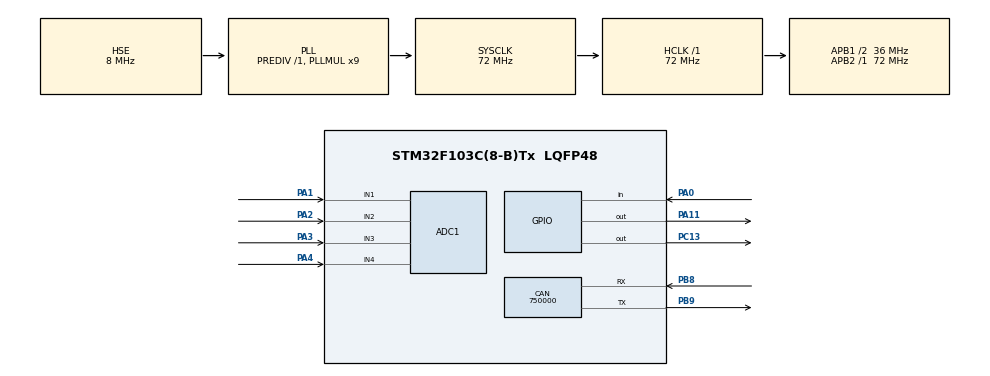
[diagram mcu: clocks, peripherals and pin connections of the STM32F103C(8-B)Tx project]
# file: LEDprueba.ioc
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Mcu.Family=STM32F1
RCC.PLLSourceVirtual=RCC_PLLSOURCE_HSE
FREERTOS.Tasks01=defaultTask,24,128,StartDefaultTask,Default,NULL,Dynamic,NULL,NULL;myTask02,24,128,StartTask02,Default,NULL,Dynamic,NULL,NULL;myTask03,16,128,StartTask03,Default,NULL,Dynamic,NULL,NULL
ADC1.Rank-0\#ChannelRegularConversion=1
PD1-OSC_OUT.Mode=HSE-External-Oscillator
SH.ADCx_IN2.0=ADC1_IN2,IN2
CAN.CalculateBaudRate=750000
PC13-TAMPER-RTC.Signal=GPIO_Output
PD0-OSC_IN.Signal=RCC_OSC_IN
RCC.APB1CLKDivider=RCC_HCLK_DIV2
CAN.CalculateTimeBit=1333.33
RCC.SYSCLKSource=RCC_SYSCLKSOURCE_PLLCLK
ProjectManager.StackSize=0x400
PA0-WKUP.Signal=GPIO_Input
VP_FREERTOS_VS_CMSIS_V2.Mode=CMSIS_V2
PD1-OSC_OUT.Signal=RCC_OSC_OUT
PA13.Signal=SYS_JTMS-SWDIO
ProjectManager.TargetToolchain=STM32CubeIDE
RCC.HCLKFreq_Value=72000000
SH.ADCx_IN3.0=ADC1_IN3,IN3
PB9.Mode=CAN_Activate
RCC.APB2TimFreq_Value=72000000
RCC.USBFreq_Value=72000000
PA1.Signal=ADCx_IN1
RCC.AHBFreq_Value=72000000
PD0-OSC_IN.Mode=HSE-External-Oscillator
ADC1.Channel-0\#ChannelRegularConversion=ADC_CHANNEL_1
board=custom
RCC.PLLMUL=RCC_PLL_MUL9
RCC.APB2Freq_Value=72000000
PA14.Mode=Serial_Wire
SH.ADCx_IN4.0=ADC1_IN4,IN4
PA13.Mode=Serial_Wire
Mcu.Name=STM32F103C(8-B)Tx
CAN.CalculateTimeQuantum=444.44444444444446
ADC1.SamplingTime-0\#ChannelRegularConversion=ADC_SAMPLETIME_1CYCLE_5
PA2.Signal=ADCx_IN2
PA4.Signal=ADCx_IN4
RCC.SYSCLKFreq_VALUE=72000000
Mcu.Package=LQFP48
PB9.Signal=CAN_TX
ADC1.master=1
PA11.Signal=GPIO_Output
PA14.Signal=SYS_JTCK-SWCLK
ProjectManager.HeapSize=0x200
NVIC.PriorityGroup=NVIC_PRIORITYGROUP_4
ADC1.NbrOfConversionFlag=1
SH.ADCx_IN1.0=ADC1_IN1,IN1
PB8.Mode=CAN_Activate
RCC.APB1TimFreq_Value=72000000
PB8.Signal=CAN_RX
RCC.APB1Freq_Value=36000000
PA3.Signal=ADCx_IN3

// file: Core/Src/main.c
/* USER CODE BEGIN Header */
/**
  ******************************************************************************
  * @file           : main.c
  * @brief          : Main program body
  ******************************************************************************
  * @attention
  *
  * <h2><center>&copy; Copyright (c) 2021 STMicroelectronics.
  * All rights reserved.</center></h2>
  *
  * This software component is licensed by ST under BSD 3-Clause license,
  * the "License"; You may not use this file except in compliance with the
  * License. You may obtain a copy of the License at:
  *                        opensource.org/licenses/BSD-3-Clause
  *
  ******************************************************************************
  */
/* USER CODE END Header */
#include "main.h"
#include "cmsis_os.h"

ADC_HandleTypeDef hadc1;

CAN_HandleTypeDef hcan;

/* Definitions for defaultTask */
osThreadId_t defaultTaskHandle;
const osThreadAttr_t defaultTask_attributes = {
  .name = "defaultTask",
  .stack_size = 128 * 4,
  .priority = (osPriority_t) osPriorityNormal,
};
/* Definitions for myTask02 */
osThreadId_t myTask02Handle;
const osThreadAttr_t myTask02_attributes = {
  .name = "myTask02",
  .stack_size = 128 * 4,
  .priority = (osPriority_t) osPriorityNormal,
};
/* Definitions for myTask03 */
osThreadId_t myTask03Handle;
const osThreadAttr_t myTask03_attributes = {
  .name = "myTask03",
  .stack_size = 128 * 4,
  .priority = (osPriority_t) osPriorityBelowNormal,
};

void SystemClock_Config(void);
static void MX_GPIO_Init(void);
static void MX_ADC1_Init(void);
static void MX_CAN_Init(void);
void StartDefaultTask(void *argument);
void StartTask02(void *argument);
void StartTask03(void *argument);

int main(void)
{

  /* MCU Configuration--------------------------------------------------------*/

  /* Reset of all peripherals, Initializes the Flash interface and the Systick. */
  HAL_Init();

  /* Configure the system clock */
  SystemClock_Config();

  /* Initialize all configured peripherals */
  MX_GPIO_Init();
  MX_ADC1_Init();
  MX_CAN_Init();
  /* USER CODE BEGIN 2 */
  //filter config
  //CAN_FilterConfig();
  //Start listening for CAN traffic with IT
 // HAL_CAN_Receive_IT(&hcan1, CAN_FIFO0);

  /* USER CODE END 2 */

  /* Init scheduler */
  osKernelInitialize();

  /* Create the thread(s) */
  /* creation of defaultTask */
  defaultTaskHandle = osThreadNew(StartDefaultTask, NULL, &defaultTask_attributes);

  /* creation of myTask02 */
  myTask02Handle = osThreadNew(StartTask02, NULL, &myTask02_attributes);

  /* creation of myTask03 */
  myTask03Handle = osThreadNew(StartTask03, NULL, &myTask03_attributes);

  /* Start scheduler */
  osKernelStart();

  /* We should never get here as control is now taken by the scheduler */
  /* Infinite loop */
  while (1)
  {

  }
}

void SystemClock_Config(void)
{
  RCC_OscInitTypeDef RCC_OscInitStruct = {0};
  RCC_ClkInitTypeDef RCC_ClkInitStruct = {0};
  RCC_PeriphCLKInitTypeDef PeriphClkInit = {0};

  /** Initializes the RCC Oscillators according to the specified parameters
  * in the RCC_OscInitTypeDef structure.
  */
  RCC_OscInitStruct.OscillatorType = RCC_OSCILLATORTYPE_HSE;
  RCC_OscInitStruct.HSEState = RCC_HSE_ON;
  RCC_OscInitStruct.HSEPredivValue = RCC_HSE_PREDIV_DIV1;
  RCC_OscInitStruct.HSIState = RCC_HSI_ON;
  RCC_OscInitStruct.PLL.PLLState = RCC_PLL_ON;
  RCC_OscInitStruct.PLL.PLLSource = RCC_PLLSOURCE_HSE;
  RCC_OscInitStruct.PLL.PLLMUL = RCC_PLL_MUL9;
  if (HAL_RCC_OscConfig(&RCC_OscInitStruct) != HAL_OK)
  {
    Error_Handler();
  }
  /** Initializes the CPU, AHB and APB buses clocks
  */
  RCC_ClkInitStruct.ClockType = RCC_CLOCKTYPE_HCLK|RCC_CLOCKTYPE_SYSCLK
                              |RCC_CLOCKTYPE_PCLK1|RCC_CLOCKTYPE_PCLK2;
  RCC_ClkInitStruct.SYSCLKSource = RCC_SYSCLKSOURCE_PLLCLK;
  RCC_ClkInitStruct.AHBCLKDivider = RCC_SYSCLK_DIV1;
  RCC_ClkInitStruct.APB1CLKDivider = RCC_HCLK_DIV2;
  RCC_ClkInitStruct.APB2CLKDivider = RCC_HCLK_DIV1;

  if (HAL_RCC_ClockConfig(&RCC_ClkInitStruct, FLASH_LATENCY_2) != HAL_OK)
  {
    Error_Handler();
  }
  PeriphClkInit.PeriphClockSelection = RCC_PERIPHCLK_ADC;
  PeriphClkInit.AdcClockSelection = RCC_ADCPCLK2_DIV2;
  if (HAL_RCCEx_PeriphCLKConfig(&PeriphClkInit) != HAL_OK)
  {
    Error_Handler();
  }
}

static void MX_ADC1_Init(void)
{

  ADC_ChannelConfTypeDef sConfig = {0};

  /** Common config
  */
  hadc1.Instance = ADC1;
  hadc1.Init.ScanConvMode = ADC_SCAN_DISABLE;
  hadc1.Init.ContinuousConvMode = DISABLE;
  hadc1.Init.DiscontinuousConvMode = DISABLE;
  hadc1.Init.ExternalTrigConv = ADC_SOFTWARE_START;
  hadc1.Init.DataAlign = ADC_DATAALIGN_RIGHT;
  hadc1.Init.NbrOfConversion = 1;
  if (HAL_ADC_Init(&hadc1) != HAL_OK)
  {
    Error_Handler();
  }
  /** Configure Regular Channel
  */
  sConfig.Channel = ADC_CHANNEL_1;
  sConfig.Rank = ADC_REGULAR_RANK_1;
  sConfig.SamplingTime = ADC_SAMPLETIME_1CYCLE_5;
  if (HAL_ADC_ConfigChannel(&hadc1, &sConfig) != HAL_OK)
  {
    Error_Handler();
  }

}

static void MX_CAN_Init(void)
{

  hcan.Instance = CAN1;
  hcan.Init.Prescaler = 16;
  hcan.Init.Mode = CAN_MODE_NORMAL;
  hcan.Init.SyncJumpWidth = CAN_SJW_1TQ;
  hcan.Init.TimeSeg1 = CAN_BS1_1TQ;
  hcan.Init.TimeSeg2 = CAN_BS2_1TQ;
  hcan.Init.TimeTriggeredMode = DISABLE;
  hcan.Init.AutoBusOff = DISABLE;
  hcan.Init.AutoWakeUp = DISABLE;
  hcan.Init.AutoRetransmission = DISABLE;
  hcan.Init.ReceiveFifoLocked = DISABLE;
  hcan.Init.TransmitFifoPriority = DISABLE;
  if (HAL_CAN_Init(&hcan) != HAL_OK)
  {
    Error_Handler();
  }

}

static void MX_GPIO_Init(void)
{
  GPIO_InitTypeDef GPIO_InitStruct = {0};

  /* GPIO Ports Clock Enable */
  __HAL_RCC_GPIOC_CLK_ENABLE();
  __HAL_RCC_GPIOD_CLK_ENABLE();
  __HAL_RCC_GPIOA_CLK_ENABLE();
  __HAL_RCC_GPIOB_CLK_ENABLE();

  /*Configure GPIO pin Output Level */
  HAL_GPIO_WritePin(GPIOC, GPIO_PIN_13, GPIO_PIN_RESET);

  /*Configure GPIO pin Output Level */
  HAL_GPIO_WritePin(GPIOA, GPIO_PIN_11, GPIO_PIN_RESET);

  /*Configure GPIO pin : PC13 */
  GPIO_InitStruct.Pin = GPIO_PIN_13;
  GPIO_InitStruct.Mode = GPIO_MODE_OUTPUT_PP;
  GPIO_InitStruct.Pull = GPIO_NOPULL;
  GPIO_InitStruct.Speed = GPIO_SPEED_FREQ_LOW;
  HAL_GPIO_Init(GPIOC, &GPIO_InitStruct);

  /*Configure GPIO pin : PA0 */
  GPIO_InitStruct.Pin = GPIO_PIN_0;
  GPIO_InitStruct.Mode = GPIO_MODE_INPUT;
  GPIO_InitStruct.Pull = GPIO_NOPULL;
  HAL_GPIO_Init(GPIOA, &GPIO_InitStruct);

  /*Configure GPIO pin : PA11 */
  GPIO_InitStruct.Pin = GPIO_PIN_11;
  GPIO_InitStruct.Mode = GPIO_MODE_OUTPUT_PP;
  GPIO_InitStruct.Pull = GPIO_NOPULL;
  GPIO_InitStruct.Speed = GPIO_SPEED_FREQ_LOW;
  HAL_GPIO_Init(GPIOA, &GPIO_InitStruct);

}

/* USER CODE BEGIN 4 */
/*
void CAN_FilterConfig(void)
{
  CAN_FilterConfTypeDef  sFilterConfig;

  sFilterConfig.BankNumber = 14;
  sFilterConfig.FilterActivation = ENABLE;
  sFilterConfig.FilterFIFOAssignment = 0;
  sFilterConfig.FilterIdHigh = 0x0000;
  sFilterConfig.FilterIdLow = 0x0000;
  sFilterConfig.FilterMaskIdHigh = 0x0000; //0xFFE0
  sFilterConfig.FilterMaskIdLow = 0x0000;
  sFilterConfig.FilterMode = CAN_FILTERMODE_IDMASK;
  sFilterConfig.FilterNumber = 0;
  sFilterConfig.FilterScale = CAN_FILTERSCALE_32BIT;

  HAL_CAN_ConfigFilter(&hcan1, &sFilterConfig);

*/

/* USER CODE END 4 */

void StartDefaultTask(void *argument)
{
  /* USER CODE BEGIN 5 */
  /* Infinite loop */
  for(;;)
  {
	  HAL_GPIO_TogglePin(GPIOC, GPIO_PIN_13);
	  HAL_Delay(500);//500 ms

  }
  /* USER CODE END 5 */
}

void StartTask02(void *argument)
{
  /* USER CODE BEGIN StartTask02 */
  /* Infinite loop */
  for(;;)
  {
	  HAL_GPIO_TogglePin(GPIOA, GPIO_PIN_11);

	  HAL_Delay(2000);//500 ms
  }
  /* USER CODE END StartTask02 */
}

void StartTask03(void *argument)
{
  /* USER CODE BEGIN StartTask03 */
  /* Infinite loop */
  for(;;)
  {
	  HAL_GPIO_TogglePin(GPIOA, GPIO_PIN_11);
	  HAL_Delay(750);//500 ms
  }
  /* USER CODE END StartTask03 */
}

void Error_Handler(void)
{
  __disable_irq();
  while (1)
  {
  }
}

/************************ (C) COPYRIGHT STMicroelectronics *****END OF FILE****/
